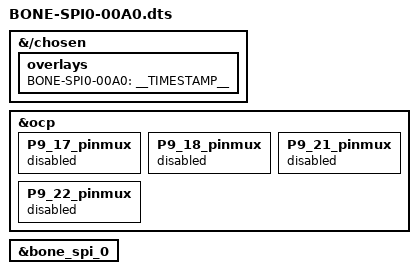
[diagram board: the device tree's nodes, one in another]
/*
 * Copyright (C) 2020 Deepak Khatri <deepaklorkhatri7@gmail.com>
 *
 * Virtual cape for /bone/spi/0.0
 *
 * This program is free software; you can redistribute it and/or modify
 * it under the terms of the GNU General Public License version 2 as
 * published by the Free Software Foundation.
 */
 
/dts-v1/;
/plugin/;

/*
* Helper to show loaded overlays under: /proc/device-tree/chosen/overlays/
*/
&{/chosen} {
    overlays {
        BONE-SPI0-00A0 = __TIMESTAMP__;
    };
};

/*
* Free up the pins used by the cape from the pinmux helpers.
*/
&ocp {
    P9_17_pinmux { status = "disabled"; };	/* P9_17 (A16) spi0_cs0.spi0_cs0 */
    P9_18_pinmux { status = "disabled"; };	/* P9_18 (B16) spi0_d1.spi0_d1 */
    P9_21_pinmux { status = "disabled"; };	/* P9_21 (B17) spi0_d0.spi0_d0 */
    P9_22_pinmux { status = "disabled"; };	/* P9_22 (A17) spi0_sclk.spi0_sclk */
};

&bone_spi_0 {
    // See these files for the definition
    // https://github.com/beagleboard/BeagleBoard-DeviceTrees/src/arm/bbai-bone-buses.dtsi
    // https://github.com/beagleboard/BeagleBoard-DeviceTrees/src/arm/bbb-bone-buses.dtsi
    status = "okay";
};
